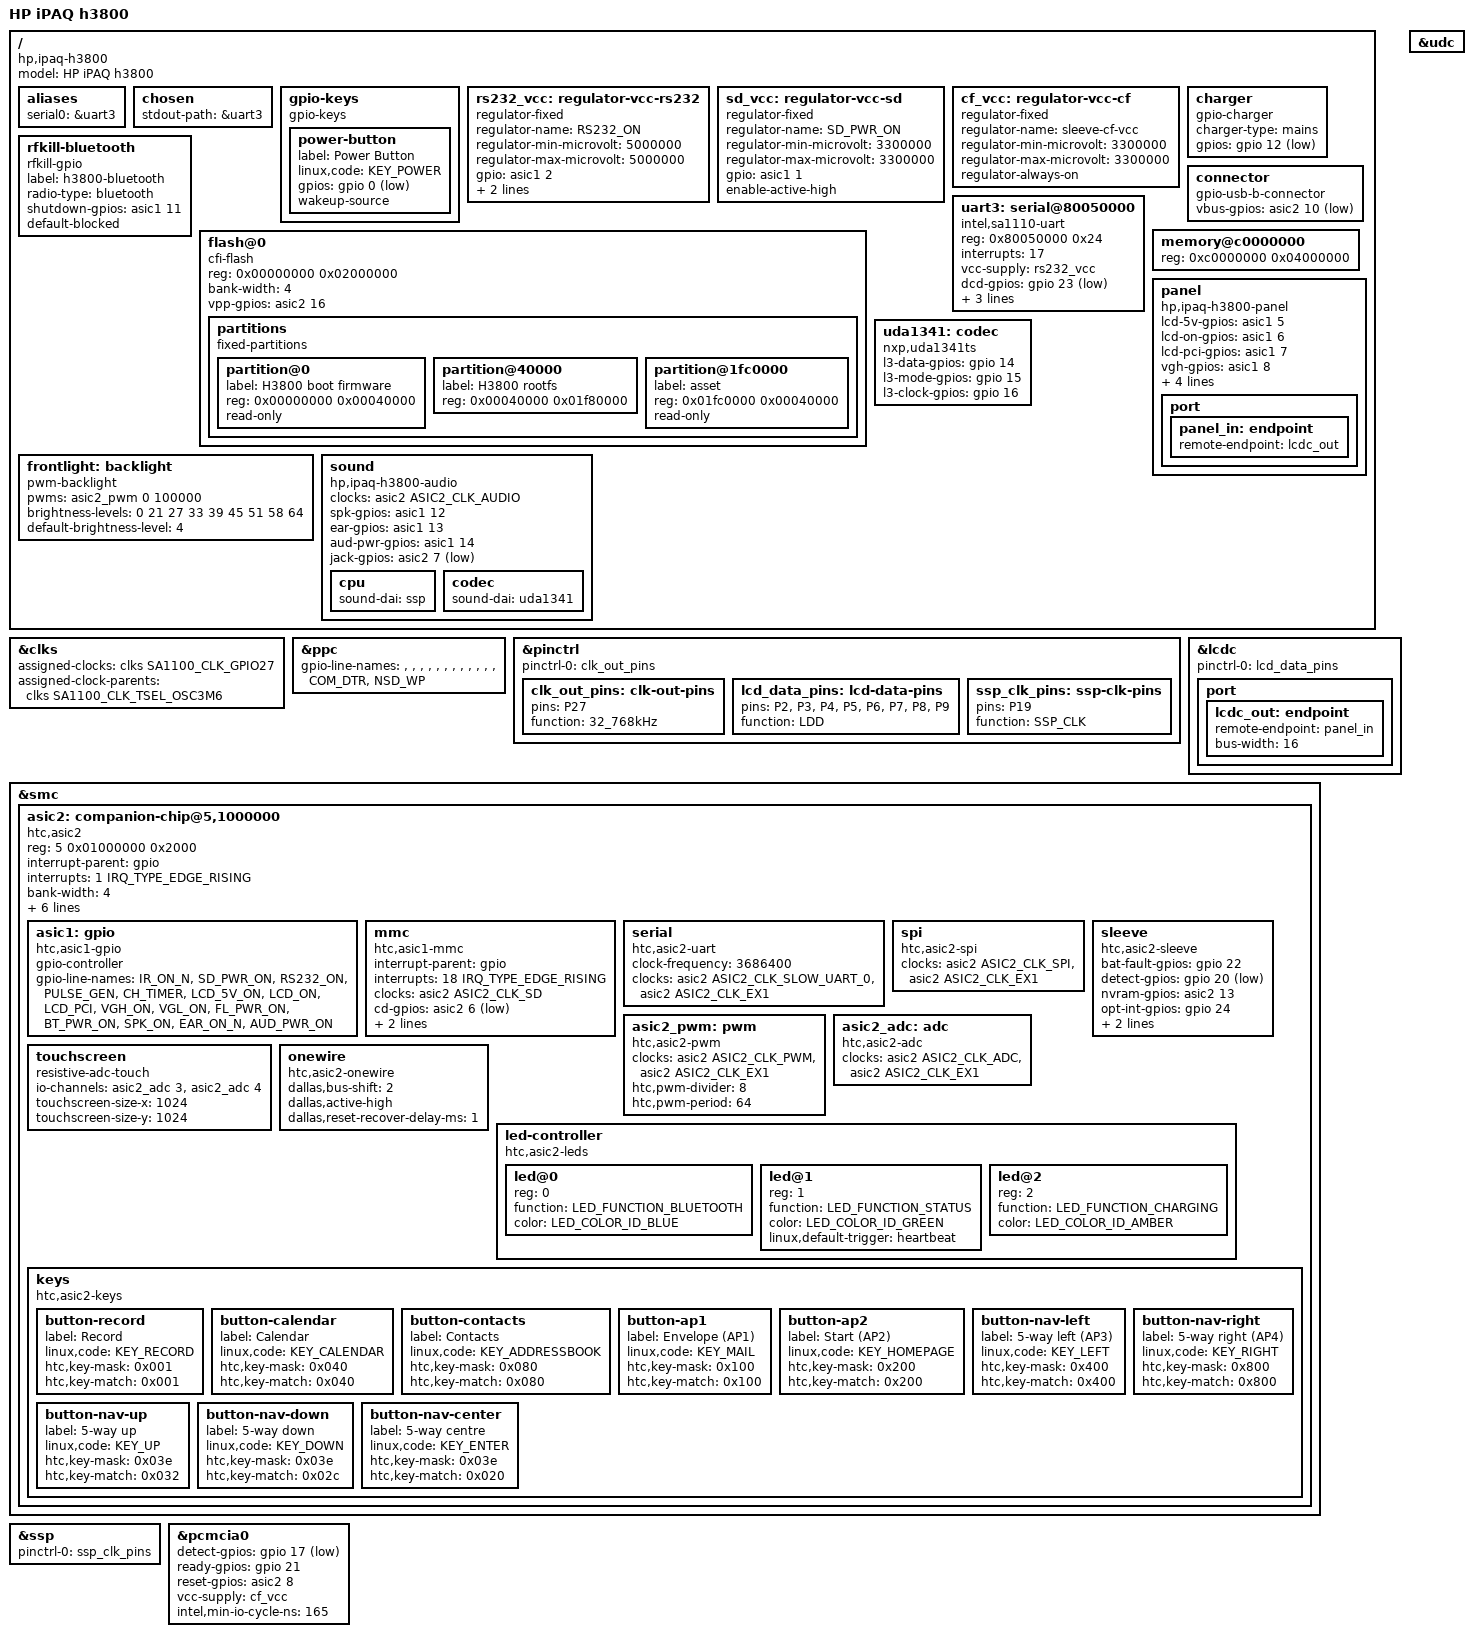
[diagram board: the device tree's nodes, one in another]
// SPDX-License-Identifier: GPL-2.0-only
/*
 * Device tree for the HP iPAQ h3800 (h38xx) family handheld
 * (h3815/h3830/h3835/h3845/h3850/h3870/h3875).
 *
 * Copyright (C) 2026 Koen Kooi
 */

/dts-v1/;

#include <dt-bindings/clock/htc,asic2.h>
#include <dt-bindings/gpio/gpio.h>
#include <dt-bindings/input/input.h>
#include <dt-bindings/interrupt-controller/irq.h>
#include <dt-bindings/leds/common.h>
#include "sa1110.dtsi"

/ {
	model = "HP iPAQ h3800";
	compatible = "hp,ipaq-h3800", "intel,sa1110";

	aliases {
		serial0 = &uart3;
	};

	chosen {
		stdout-path = &uart3;
	};

	/*
	 * The power button is on GPIO0, active low, and wakes the system on
	 * both edges. It is not the gpio-keys that h3xxx_mach_init() would
	 * register: that one sits on GPIO18, which is the MMC_INT line of this
	 * board, and reusing it would take the completion interrupt of the SD
	 * host.
	 */
	gpio-keys {
		compatible = "gpio-keys";

		power-button {
			label = "Power Button";
			linux,code = <KEY_POWER>;
			gpios = <&gpio 0 GPIO_ACTIVE_LOW>;
			wakeup-source;
		};
	};

	/*
	 * Enable of the RS232 transceiver (ASIC1 GPIO bit 2); the console
	 * produces no output until it is driven. regulator-boot-on drives it
	 * as soon as the regulator probes, and the serial driver holds it
	 * from then on for as long as the port is the console.
	 */
	rs232_vcc: regulator-vcc-rs232 {
		compatible = "regulator-fixed";
		regulator-name = "RS232_ON";
		regulator-min-microvolt = <5000000>;
		regulator-max-microvolt = <5000000>;
		gpio = <&asic1 2 GPIO_ACTIVE_HIGH>;
		enable-active-high;
		regulator-boot-on;
	};

	/*
	 * SD_PWR_ON, the supply of the SD slot, is a GPIO-backed fixed
	 * regulator that the "mmc" node consumes as its vmmc-supply. It has no
	 * regulator-boot-on because nothing needs it before the SD host driver
	 * powers it up.
	 */
	sd_vcc: regulator-vcc-sd {
		compatible = "regulator-fixed";
		regulator-name = "SD_PWR_ON";
		regulator-min-microvolt = <3300000>;
		regulator-max-microvolt = <3300000>;
		gpio = <&asic1 1 GPIO_ACTIVE_HIGH>;
		enable-active-high;
	};

	/*
	 * The CF card's Vcc rail. The sleeve has no per-card Vcc switch, so
	 * this is a fixed, always-on 3.3 V supply with no gpio, present so
	 * that "&pcmcia0" below has a real supply to consume.
	 */
	cf_vcc: regulator-vcc-cf {
		compatible = "regulator-fixed";
		regulator-name = "sleeve-cf-vcc";
		regulator-min-microvolt = <3300000>;
		regulator-max-microvolt = <3300000>;
		regulator-always-on;
	};

	/*
	 * AC adapter presence. GPIO12 is AC_IN, which reads low when an
	 * adapter is present, so it is active low.
	 *
	 * There is no adc-battery node as on the h39xx: the ADC channel that
	 * would read the battery voltage is not used on this board by any
	 * known firmware.
	 *
	 * The charge enable line, bit 4 of ASIC1's GPIO bank (CH_TIMER, high
	 * while charging), is not given to gpio-charger as
	 * charge-enable-gpios: the driver asserts it at probe, and the
	 * factory firmware ends a charge itself on a full cell, over
	 * temperature, a battery fault or after eight hours, none of which
	 * the kernel implements for this board. The line stays as the boot
	 * loader left it.
	 */
	charger {
		compatible = "gpio-charger";
		charger-type = "mains";
		gpios = <&gpio 12 GPIO_ACTIVE_LOW>;
	};

	/*
	 * BT_PWR_ON (bit 11 of ASIC1's GPIO bank) powers the radio of the
	 * h3870 and h3875. It is driven separately from the ASIC2 UART0
	 * transport rather than tied to opening the tty. The same devicetree
	 * serves the models without a radio, so the switch registers blocked:
	 * rfkill-gpio drives the line high while it probes and drops it again
	 * when the blocked switch registers, and the rail stays off until
	 * userspace unblocks the switch before attaching the radio.
	 */
	rfkill-bluetooth {
		compatible = "rfkill-gpio";
		label = "h3800-bluetooth";
		radio-type = "bluetooth";
		shutdown-gpios = <&asic1 11 GPIO_ACTIVE_HIGH>;
		default-blocked;
	};

	/*
	 * VBUS sensing for the USB gadget is ASIC2 GPIO bit 10 (USB_DETECT_N),
	 * active low. The gpio-usb-b-connector compatible makes the gpio-vbus
	 * USB PHY driver bind; the UDC finds that PHY by type, so no phandle
	 * is needed. The board has no software D+ pull-up, so the host sees
	 * an attach whenever VBUS is present.
	 */
	connector {
		compatible = "gpio-usb-b-connector", "usb-b-connector";
		vbus-gpios = <&asic2 10 GPIO_ACTIVE_LOW>;
	};

	/*
	 * Ser3 is the only UART of this board that is a tty and its console;
	 * Ser1 is used for plain GPIO (see &ppc below) and Ser2 is IrDA only.
	 * The modem control lines are active low because the RS232
	 * transceiver inverts them. DTR is Ser1's TXD1 pin, the COM_DTR line
	 * of &ppc; it is deasserted until the port is opened, as the factory
	 * firmware does.
	 */
	uart3: serial@80050000 {
		compatible = "intel,sa1110-uart", "intel,sa1100-uart";
		reg = <0x80050000 0x24>;
		interrupts = <17>;
		vcc-supply = <&rs232_vcc>;
		dcd-gpios = <&gpio 23 GPIO_ACTIVE_LOW>;
		cts-gpios = <&gpio 25 GPIO_ACTIVE_LOW>;
		rts-gpios = <&gpio 26 GPIO_ACTIVE_LOW>;
		dtr-gpios = <&ppc 12 GPIO_ACTIVE_LOW>;
	};

	/*
	 * On-board NOR flash on CS0: an Intel 28F320J3, 28F640J3 or 28F128J3
	 * (4, 8 or 16 MiB, device IDs 0x16, 0x17 and 0x18), two x16 chips
	 * interleaved onto the 32-bit bus when a second chip also reports
	 * manufacturer 0x89, hence a bank-width of 4. The reg property maps
	 * 32 MiB, two of the largest chips, as the h3xxx board code does: CFI
	 * probing only finds what is populated inside the window and the MTD
	 * partition code truncates, with a warning, a partition that extends
	 * past the detected size, so the same node works on every variant. The
	 * boot firmware takes the first 256 KiB. On a 32 MiB unit the top 256
	 * KiB is an asset block with per-unit identity data that the factory
	 * firmware reads, so it is a read-only partition of its own. Where that
	 * block sits on a 16 MiB unit is not known; there the "asset" partition
	 * lies past the detected size and the MTD partition code disables it.
	 *
	 * vpp-gpios is the FlashWP_VPP_ON line of ASIC2 (offset 16 of its
	 * GPIO chip), active high. physmap-core only drives it around an erase
	 * or program operation.
	 *
	 * This node needs no board code, since physmap-core matches "cfi-flash"
	 * and the node is populated by of_platform_default_populate(). It is
	 * left at the root rather than put under the static memory controller
	 * with ASIC2: nCS0 has no known access timing, and a child that carries
	 * none of the timing properties leaves its chip select as the boot
	 * firmware programmed it, which is the only safe option for the
	 * device the kernel was fetched through. The probe is deferred until
	 * the gpio chip of ASIC2 that backs vpp-gpios exists.
	 */
	flash@0 {
		compatible = "cfi-flash";
		reg = <0x00000000 0x02000000>;
		bank-width = <4>;
		vpp-gpios = <&asic2 16 GPIO_ACTIVE_HIGH>;

		partitions {
			compatible = "fixed-partitions";
			#address-cells = <1>;
			#size-cells = <1>;

			partition@0 {
				label = "H3800 boot firmware";
				reg = <0x00000000 0x00040000>;
				read-only;
			};

			partition@40000 {
				label = "H3800 rootfs";
				reg = <0x00040000 0x01f80000>;
			};

			partition@1fc0000 {
				label = "asset";
				reg = <0x01fc0000 0x00040000>;
				read-only;
			};
		};
	};

	memory@c0000000 {
		device_type = "memory";
		/*
		 * 64 MiB. The h3830 has 32 MiB and needs its size from the boot
		 * loader: a DTB the boot loader edits, or the ATAG memory size
		 * merged by ARM_ATAG_DTB_COMPAT into an appended DTB.
		 */
		reg = <0xc0000000 0x04000000>;
	};

	/*
	 * The panel driver sequences all six rails, including the frontlight
	 * power rail FL_PWR_ON, so that the pin has a single owner.
	 */
	panel {
		compatible = "hp,ipaq-h3800-panel";

		lcd-5v-gpios  = <&asic1 5 GPIO_ACTIVE_HIGH>;
		lcd-on-gpios  = <&asic1 6 GPIO_ACTIVE_HIGH>;
		lcd-pci-gpios = <&asic1 7 GPIO_ACTIVE_HIGH>;
		vgh-gpios     = <&asic1 8 GPIO_ACTIVE_HIGH>;
		vgl-gpios     = <&asic1 9 GPIO_ACTIVE_HIGH>;
		fl-pwr-gpios  = <&asic1 10 GPIO_ACTIVE_HIGH>;

		/*
		 * The glass is physically portrait. The mounting correction is
		 * 270, DRM_MODE_PANEL_ORIENTATION_LEFT_UP. The h3900, which has
		 * the same case and panel size, uses 90, but the two are not
		 * mounted the same way: with 90 the image of the one h3870
		 * checked is rotated 180 degrees from correct.
		 */
		rotation = <270>;
		backlight = <&frontlight>;

		port {
			panel_in: endpoint {
				remote-endpoint = <&lcdc_out>;
			};
		};
	};

	/*
	 * No enable-gpios: the panel driver owns FL_PWR_ON.
	 *
	 * The period in pwms is only used by pwm-backlight to scale the duty
	 * cycle: the PWM driver ignores the requested period and always
	 * programs the fixed hardware period from the asic2_pwm node.
	 */
	frontlight: backlight {
		compatible = "pwm-backlight";
		pwms = <&asic2_pwm 0 100000>;

		/*
		 * The duty range of the hardware is 0-64, and the PWM driver
		 * clamps any non-zero duty below 21 (about 33%) up to 21. Level
		 * 0 is off; the other levels step evenly from that floor to
		 * full scale, so no listed level needs clamping.
		 */
		brightness-levels = <0 21 27 33 39 45 51 58 64>;
		default-brightness-level = <4>;
	};

	/*
	 * The UDA1341TS audio codec, controlled over L3 bit-banged on three
	 * plain SA-1110 core GPIOs: GPIO14 DATA, 15 MODE, 16 CLOCK. They are
	 * not part of any companion-chip window and carry no competing
	 * alternate function, so plain "&gpio" phandles suffice.
	 */
	uda1341: codec {
		compatible = "nxp,uda1341ts";

		l3-data-gpios  = <&gpio 14 GPIO_ACTIVE_HIGH>;
		l3-mode-gpios  = <&gpio 15 GPIO_ACTIVE_HIGH>;
		l3-clock-gpios = <&gpio 16 GPIO_ACTIVE_HIGH>;

		#sound-dai-cells = <0>;
	};

	/*
	 * The machine driver tying the SSP CPU DAI and the codec together.
	 * It alone owns and synchronizes the three rate-dependent settings
	 * (ASIC2 clock tap, SSP SerClkDiv, codec STATUS0 SC field) so that
	 * the 32*fs bit-clock invariant of the hardware never drifts, along
	 * with the speaker/headphone routing and the jack-detect debounce.
	 *
	 * spk-gpios, ear-gpios and aud-pwr-gpios are bits 12, 13 and 14 of
	 * ASIC1 (SPK_ON, EAR_ON_N, AUD_PWR_ON), all GPIO_ACTIVE_HIGH so that
	 * the "set/clear the bit" logic of the driver matches the routing
	 * truth table literally; the _N in EAR_ON_N is part of the signal
	 * name, not a polarity property. jack-gpios is bit 7 of ASIC2 GPIO2
	 * (EAR_IN_N), genuinely active low.
	 */
	sound {
		compatible = "hp,ipaq-h3800-audio";

		clocks = <&asic2 ASIC2_CLK_AUDIO>;
		clock-names = "audio";

		spk-gpios = <&asic1 12 GPIO_ACTIVE_HIGH>;
		ear-gpios = <&asic1 13 GPIO_ACTIVE_HIGH>;
		aud-pwr-gpios = <&asic1 14 GPIO_ACTIVE_HIGH>;
		jack-gpios = <&asic2 7 GPIO_ACTIVE_LOW>;

		cpu {
			sound-dai = <&ssp>;
		};

		codec {
			sound-dai = <&uda1341>;
		};
	};
};

/*
 * The ASIC2 UART blocks take their 3.6864 MHz reference from GPIO27. TSEL 1
 * and TSEL 5 both select that oscillator; 1 is the tap the SA-1111 boards
 * and the 2.4 kernel's h3800_map_io() use, and the one an h3870 has run
 * with. The other TUCR fields stay as the boot loader left them.
 */
&clks {
	assigned-clocks = <&clks SA1100_CLK_GPIO27>;
	assigned-clock-parents = <&clks SA1100_CLK_TSEL_OSC3M6>;
};

/* The two lines of the PPC block that this board uses. */
&ppc {
	gpio-line-names = "", "", "", "", "", "", "", "", "", "", "", "",
			  "COM_DTR", "NSD_WP";
};

/*
 * LDD<15:8>, the upper byte of each RGB565 pixel, are muxed onto GPIO<9:2>
 * and need both GAFR and GPDR set for the LCD controller to drive them.
 * h3xxx_map_io() unconditionally does "GPDR = 0", which turns them into
 * floating alternate-function inputs, so the panel shows a strong colour
 * cast over an otherwise correct image. The pinctrl default state is applied
 * before the LCD controller probes. "pins" lists P2..P9 individually because
 * devicetree has no range syntax; "LDD" is the single function name the
 * binding gives the whole 8-bit data bus.
 */
&pinctrl {
	pinctrl-names = "default";
	pinctrl-0 = <&clk_out_pins>;

	/*
	 * GPIO27 carries the test clock that "&clks" selects, the reference
	 * of the ASIC2 UARTs. No driver owns the pin, so the pin controller
	 * holds the state itself.
	 */
	clk_out_pins: clk-out-pins {
		pins = "P27";
		function = "32_768kHz";
	};

	lcd_data_pins: lcd-data-pins {
		pins = "P2", "P3", "P4", "P5", "P6", "P7", "P8", "P9";
		function = "LDD";
	};

	ssp_clk_pins: ssp-clk-pins {
		pins = "P19";
		function = "SSP_CLK";
	};
};

&lcdc {
	status = "okay";
	pinctrl-names = "default";
	pinctrl-0 = <&lcd_data_pins>;

	port {
		lcdc_out: endpoint {
			remote-endpoint = <&panel_in>;
			bus-width = <16>;
		};
	};
};

&smc {
	status = "okay";

	/*
	 * ASIC2 companion chip on nCS5 + 0x01000000, interrupting the SoC on
	 * GPIO1 (rising edge). Its register map is the same as the h39xx's.
	 *
	 * The node sits under the static memory controller because the
	 * variable-latency I/O timing of nCS5 has to be right before the first
	 * access into this window: that chip select has no bus error timeout,
	 * so a stuck cycle hangs the core and starves DRAM refresh with it. The
	 * driver of the controller guarantees the order by writing the timing
	 * of every child before it instantiates the children.
	 *
	 * The four timing properties are the nCS5 half of MSC2, 0xe451, that
	 * the original firmware programs, split into the fields the controller
	 * driver writes back:
	 *   RT  = 1  -> "vlio"             0x0001
	 *   RBW = 0  -> bank-width = <4>   0x0000
	 *   RDF = 10 -> first access 11    0x0050
	 *   RDN = 4  -> next access 5      0x0400
	 *   RRR = 7  -> recovery 14        0xe000
	 * RDF and RDN encode cycles minus one and RRR counts cycle pairs, so
	 * these numbers reassemble to exactly 0xe451.
	 *
	 * "interrupts" is the only source of the interrupt for asic2_probe().
	 * A probe that finds the SoC GPIO interrupt controller not yet up is
	 * deferred and retried by the driver core.
	 */
	asic2: companion-chip@5,1000000 {
		compatible = "htc,asic2";
		reg = <5 0x01000000 0x2000>;

		interrupt-parent = <&gpio>;
		interrupts = <1 IRQ_TYPE_EDGE_RISING>;

		bank-width = <4>;
		intel,sa1110-smc-type = "vlio";
		intel,sa1110-smc-first-access-cycles = <11>;
		intel,sa1110-smc-next-access-cycles = <5>;
		intel,sa1110-smc-recovery-cycles = <14>;

		gpio-controller;
		#gpio-cells = <2>;

		/*
		 * Every clock gate of the chip is exposed here, indexed by the
		 * ASIC2_CLK_* constants. That includes ASIC2_CLK_AUDIO, the
		 * audio-clock tap selector (CLOCK_Enable[3:0]), which the
		 * "sound" node below switches among its four fixed
		 * EX1/EX2-derived rates.
		 */
		#clock-cells = <1>;

		/*
		 * The SD card clock is the shared SD selector of ASIC2. The tap
		 * of this board is 33.869 MHz, which is shared with 44.1 kHz
		 * audio; without this property the selector keeps its default,
		 * which is the tap the h39xx uses.
		 */
		htc,sd-clock-hz = <33869000>;

		/*
		 * ASIC1's 15-line GPIO block. ASIC1 is a separate chip without
		 * a chip select of its own, reached through the window of this
		 * node, and the MFD core only adds the cell when this child
		 * exists. Every line is a power-rail or routing output.
		 */
		asic1: gpio {
			compatible = "htc,asic1-gpio";
			gpio-controller;
			#gpio-cells = <2>;
			gpio-line-names = "IR_ON_N", "SD_PWR_ON", "RS232_ON",
					  "PULSE_GEN", "CH_TIMER", "LCD_5V_ON",
					  "LCD_ON", "LCD_PCI", "VGH_ON", "VGL_ON",
					  "FL_PWR_ON", "BT_PWR_ON", "SPK_ON",
					  "EAR_ON_N", "AUD_PWR_ON";
		};

		/*
		 * ASIC1's SD/MMC host. It has no reg for the same reason as
		 * "asic1" above. Unlike that block its completion interrupt
		 * is a dedicated SoC GPIO (MMC_INT) instead of anything in the
		 * demultiplexer of ASIC2, so it has its own "interrupts" against
		 * "&gpio", edge-rising like the interrupt of ASIC2.
		 *
		 * Card detect is bit 6 of the GPIO bank of ASIC2, active low, as
		 * on the h39xx. Write protect is the PPC_RXD1 line (NSD_WP on
		 * "&ppc"), active high despite its name. The factory firmware
		 * reads the SD_CON_SLT strap (ASIC2 GPIO bank bit 11) at boot and
		 * takes both polarities from it: a card is present when bit 6
		 * differs from the strap, and write protected when NSD_WP equals
		 * it. Card detect works active low on the h3870, which implies a
		 * strap reading 1 there and so an active-high write protect. With
		 * the line described active low, the h3870 registered the one
		 * card tried as read-only and listed NSD_WP as low, and that
		 * card's CSD write-protect bits were clear. The strap and the
		 * card's lock tab were not read.
		 */
		mmc {
			compatible = "htc,asic1-mmc";
			interrupt-parent = <&gpio>;
			interrupts = <18 IRQ_TYPE_EDGE_RISING>;
			clocks = <&asic2 ASIC2_CLK_SD>;
			cd-gpios = <&asic2 6 GPIO_ACTIVE_LOW>;
			wp-gpios = <&ppc 13 GPIO_ACTIVE_HIGH>;
			vmmc-supply = <&sd_vcc>;
		};

		/*
		 * UART0 of ASIC2, the Bluetooth transport of the h3870 and
		 * h3875, bound by drivers/tty/serial/8250/8250_asic2.c. The MFD
		 * core adds this cell only because the node is present and
		 * available. Like the other cells it has no reg: the MFD core
		 * hands over the sub-window and the demultiplexed interrupt.
		 * clock-frequency is the 3.6864 MHz reference that the SA-1110
		 * supplies on GPIO27, not the 24.576 MHz crystal of ASIC2. The
		 * radio is attached from userspace with hciattach, so no serdev
		 * child belongs here.
		 */
		serial {
			compatible = "htc,asic2-uart";
			clock-frequency = <3686400>;
			clocks = <&asic2 ASIC2_CLK_SLOW_UART_0>, <&asic2 ASIC2_CLK_EX1>;
			clock-names = "sel", "ex1";
		};

		/*
		 * The SPI block of ASIC2. Its register window and interrupt come
		 * from the MFD core, not from this node, which exists so that the
		 * controller has a device_node: that is how the sleeve driver
		 * finds it. There are no child nodes, as the only two devices on
		 * the bus, the ID EEPROM and the microcontroller of the option
		 * jacket that is plugged in, have no fixed identity and are
		 * allocated at probe time.
		 */
		spi {
			compatible = "htc,asic2-spi";
			clocks = <&asic2 ASIC2_CLK_SPI>, <&asic2 ASIC2_CLK_EX1>;
			clock-names = "ref", "ex1";
		};

		/*
		 * Expansion pack ("sleeve" or "option jacket") backend of the
		 * generic iPAQ sleeve bus. The 100-pin connector, the ASIC2 GPIO
		 * control bits and the ID EEPROM protocol are those of the h39xx;
		 * only the SoC lines differ: jacket presence is GPIO20 (NOPT_IND,
		 * active low), the OPT_INT line of the connector is GPIO24 and
		 * the battery fault line is GPIO22, active high, which the
		 * factory keyboard driver tests as "GPLR bit 22 set". All are
		 * ordinary GPIOs without alternate function muxing, and no other
		 * node in this file uses them.
		 *
		 * nvram, power and reset are bits 13, 12 and 9 of the ASIC2 GPIO
		 * bank. Bit 8 (OPT_PCM_RESET, the reset of a single PCMCIA card as
		 * opposed to the reset of the whole jacket at bit 9) is not
		 * listed because the PCMCIA socket driver requests it as its own
		 * reset GPIO.
		 */
		sleeve {
			compatible = "htc,asic2-sleeve";

			bat-fault-gpios = <&gpio 22 GPIO_ACTIVE_HIGH>;
			detect-gpios = <&gpio 20 GPIO_ACTIVE_LOW>;
			nvram-gpios = <&asic2 13 GPIO_ACTIVE_HIGH>;
			opt-int-gpios = <&gpio 24 GPIO_ACTIVE_HIGH>;
			power-gpios = <&asic2 12 GPIO_ACTIVE_HIGH>;
			reset-gpios = <&asic2 9 GPIO_ACTIVE_HIGH>;
		};

		/*
		 * ASIC2 PWM0 drives the frontlight, see the "frontlight" node.
		 * The divider and period are the values this board needs
		 * instead of the driver's defaults.
		 */
		asic2_pwm: pwm {
			compatible = "htc,asic2-pwm";
			#pwm-cells = <2>;
			clocks = <&asic2 ASIC2_CLK_PWM>, <&asic2 ASIC2_CLK_EX1>;
			clock-names = "ref", "ex1";
			htc,pwm-divider = <8>;
			htc,pwm-period = <64>;
		};

		/*
		 * The ADC of ASIC2, which also serves the resistive touchscreen.
		 * Labelled so that the "touchscreen" node below reaches it through
		 * a real "io-channels" phandle: a probe-ordering race against this
		 * node then becomes an ordinary deferred probe instead of a
		 * permanent failure. The light sensor on channel 0 has no consumer
		 * node yet.
		 */
		asic2_adc: adc {
			compatible = "htc,asic2-adc";
			#io-channel-cells = <1>;
			clocks = <&asic2 ASIC2_CLK_ADC>, <&asic2 ASIC2_CLK_EX1>;
			clock-names = "ref", "ex1";
		};

		/*
		 * The generic resistive-adc-touch driver, consuming the two
		 * touch-plate channels of the ADC block above. The cell values 3
		 * and 4 are the positions of TP_X0 and TP_Y1 in asic2-adc.c's
		 * channel array: that driver installs no fwnode_xlate, so IIO
		 * indexes the channels directly by this cell value. There is no
		 * "touchscreen-x-plate-ohms" and there are no z1/z2 channels, since
		 * asic2-adc.c synthesises only x and y and the pressure path of
		 * resistive-adc-touch is optional. The size is the ADC's real 10
		 * bits.
		 */
		touchscreen {
			compatible = "resistive-adc-touch";
			io-channels = <&asic2_adc 3>, <&asic2_adc 4>;
			io-channel-names = "x", "y";
			touchscreen-size-x = <1024>;
			touchscreen-size-y = <1024>;
		};

		/*
		 * The 1-Wire master of the chip, with the tunables
		 * drivers/mfd/asic2.c otherwise hardcodes: bus-shift 2, an
		 * active-high interrupt (the h3800 firmware programs the IAS bit of
		 * the interrupt enable register) and a 1 ms reset recovery delay.
		 */
		onewire {
			compatible = "htc,asic2-onewire", "dallas,ds1wm";
			dallas,bus-shift = <2>;
			dallas,active-high;
			dallas,reset-recover-delay-ms = <1>;
		};

		/*
		 * The three status LEDs. The channel numbers follow the
		 * handhelds.org 2.4 kernel's blue, green, yellow order, which is
		 * the only source that ties a colour to a channel; the colour of
		 * channel 2 is inferred from its "yellow" name, hence amber.
		 *
		 * Channel 0 (Bluetooth) has no default trigger, userspace and
		 * rfkill drive it. Channel 1 (status) runs "heartbeat", which is
		 * the only diagnostic on a board whose console is serial.
		 * Channel 2 (charging) has no default trigger on purpose. The
		 * power supply trigger for it would be
		 * "ds2760-battery.0-charging-blink-full-solid", but a devicetree
		 * default trigger is resolved synchronously inside
		 * led_classdev_register_ext(), and that trigger cannot exist yet
		 * this early in boot because the ds2760-battery device has not
		 * registered. The fallback, request_module_nowait(), still waits
		 * for the modprobe helper to be exec'd, which cannot happen
		 * before usermode helpers are enabled, so the probe hangs and
		 * takes the rest of asic2_probe() with it. Assign the trigger
		 * from userspace once the gauge is ready.
		 *
		 * Solid on is a period equal to the duty cycle, so there is no
		 * separate bit for it.
		 */
		led-controller {
			compatible = "htc,asic2-leds";
			#address-cells = <1>;
			#size-cells = <0>;

			led@0 {
				reg = <0>;
				function = LED_FUNCTION_BLUETOOTH;
				color = <LED_COLOR_ID_BLUE>;
			};

			led@1 {
				reg = <1>;
				function = LED_FUNCTION_STATUS;
				color = <LED_COLOR_ID_GREEN>;
				linux,default-trigger = "heartbeat";
			};

			led@2 {
				reg = <2>;
				function = LED_FUNCTION_CHARGING;
				color = <LED_COLOR_ID_AMBER>;
			};
		};

		/*
		 * The KPIO keypad. A key is pressed when
		 * (~Data & htc,key-mask) == htc,key-match, which is why each key
		 * has its own child node: the bits of the 5-way pad
		 * combine, and a matrix "linux,keymap" cannot express that.
		 */
		keys {
			compatible = "htc,asic2-keys";

			button-record {
				label = "Record";
				linux,code = <KEY_RECORD>;
				htc,key-mask = <0x001>;
				htc,key-match = <0x001>;
			};

			button-calendar {
				label = "Calendar";
				linux,code = <KEY_CALENDAR>;
				htc,key-mask = <0x040>;
				htc,key-match = <0x040>;
			};

			button-contacts {
				label = "Contacts";
				linux,code = <KEY_ADDRESSBOOK>;
				htc,key-mask = <0x080>;
				htc,key-match = <0x080>;
			};

			button-ap1 {
				label = "Envelope (AP1)";
				linux,code = <KEY_MAIL>;
				htc,key-mask = <0x100>;
				htc,key-match = <0x100>;
			};

			button-ap2 {
				label = "Start (AP2)";
				linux,code = <KEY_HOMEPAGE>;
				htc,key-mask = <0x200>;
				htc,key-match = <0x200>;
			};

			button-nav-left {
				label = "5-way left (AP3)";
				linux,code = <KEY_LEFT>;
				htc,key-mask = <0x400>;
				htc,key-match = <0x400>;
			};

			button-nav-right {
				label = "5-way right (AP4)";
				linux,code = <KEY_RIGHT>;
				htc,key-mask = <0x800>;
				htc,key-match = <0x800>;
			};

			button-nav-up {
				label = "5-way up";
				linux,code = <KEY_UP>;
				htc,key-mask = <0x03e>;
				htc,key-match = <0x032>;
			};

			button-nav-down {
				label = "5-way down";
				linux,code = <KEY_DOWN>;
				htc,key-mask = <0x03e>;
				htc,key-match = <0x02c>;
			};

			button-nav-center {
				label = "5-way centre";
				linux,code = <KEY_ENTER>;
				htc,key-mask = <0x03e>;
				htc,key-match = <0x020>;
			};
		};
	};
};

&ssp {
	pinctrl-names = "default";
	pinctrl-0 = <&ssp_clk_pins>;
	status = "okay";
};

&udc {
	status = "okay";
};

/*
 * CF card in the expansion sleeve, on PC Card socket 0. "detect" (GPIO17,
 * CD0) and "ready" (GPIO21, RDY0/IRQ0) are the SoC-side lines, the same
 * pair on every h3xxx generation; the socket's interrupts are derived from
 * these two GPIOs by gpiod_to_irq() in the PCMCIA core, which is why there
 * is no "interrupts" property. "reset" is ASIC2 GPIO2 bit 8 (OPT_PCM_RESET),
 * the per-card reset as distinct from the whole-jacket OPT_RESET at bit 9
 * that the "sleeve" node owns. Until ASIC2 has probed, that phandle leaves
 * the socket in deferred probe.
 *
 * A CF card read its IDENTIFY data correctly at the 165 ns default I/O
 * cycle and returned a reproducible single-bit corruption at a negotiated
 * 70 ns and 80 ns on one h3800 unit, so the socket's I/O cycle is held at
 * 165 ns or more.
 */
&pcmcia0 {
	status = "okay";

	detect-gpios = <&gpio 17 GPIO_ACTIVE_LOW>;
	ready-gpios = <&gpio 21 GPIO_ACTIVE_HIGH>;
	reset-gpios = <&asic2 8 GPIO_ACTIVE_HIGH>;
	vcc-supply = <&cf_vcc>;
	intel,min-io-cycle-ns = <165>;
};
